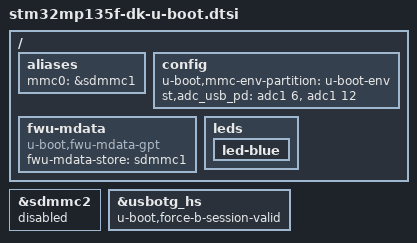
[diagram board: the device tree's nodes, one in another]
// SPDX-License-Identifier: GPL-2.0-or-later OR BSD-3-Clause
/*
 * Copyright (C) 2022, STMicroelectronics - All Rights Reserved
 */

#include "stm32mp13-u-boot.dtsi"

/ {
	aliases {
		mmc0 = &sdmmc1;
	};

	config {
		u-boot,mmc-env-partition = "u-boot-env";
		st,adc_usb_pd = <&adc1 6>, <&adc1 12>;
	};

	fwu-mdata {
		compatible = "u-boot,fwu-mdata-gpt";
		fwu-mdata-store = <&sdmmc1>;
	};

	leds {
		led-blue {
			/delete-property/default-state;
		};
	};
};

&sdmmc2 {
	status = "disabled";
};

&usbotg_hs {
	u-boot,force-b-session-valid;
};
